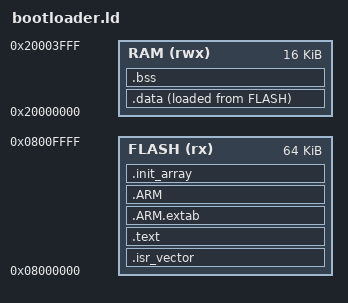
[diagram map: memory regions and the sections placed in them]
MEMORY
{
    FLASH (rx)  : ORIGIN = 0x08000000, LENGTH = 64K /* Sectors 0-3 used */
    RAM   (rwx) : ORIGIN = 0x20000000, LENGTH = 16K
}

ENTRY(Reset_Handler)

_estack = ORIGIN(RAM) + LENGTH(RAM);

SECTIONS
{
    .isr_vector :
    {
        . = ALIGN(4);
        KEEP(*(.isr_vector))
        . = ALIGN(4);
    } > FLASH

    .text :
    {
        . = ALIGN(4);
        _stext = .;
        *(.text)
        *(.text*)
        *(.rodata)
        *(.rodata*)
        . = ALIGN(4);
        _etext = .;
    } >FLASH

    /* Mandatory GCC Sections */
    .ARM.extab :
    {
        *(.ARM.extab* .gnu.linkonce.armextab.*)
    } > FLASH

    .ARM :
    {
        __exidx_start = .;
        *(.ARM.exidx*)
        __exidx_end = .;
    } > FLASH

    .init_array :
    {
        PROVIDE_HIDDEN(__init_array_start = .);
        KEEP(*(SORT(.init_array.*)))
        KEEP(*(.init_array))
        PROVIDE_HIDDEN(__init_array_end = .);
    } > FLASH

    _sidata = LOADADDR(.data);

    .data :
    {
        . = ALIGN(4);
        _sdata = .;
        *(.data)
        *(.data*)
        . = ALIGN(4);
        _edata = .;
    } > RAM AT > FLASH

    .bss (NOLOAD) :
    {
        . = ALIGN(4);
        _sbss = .;
        *(.bss)
        *(.bss*)
        *(COMMON)
        . = ALIGN(4);
        _ebss = .;
    } > RAM

    PROVIDE(_end = .);
}

ASSERT(_ebss + 1K <= _estack, "RAM overflow: not enough room for stack") /* Check that we have enough room for stack */
